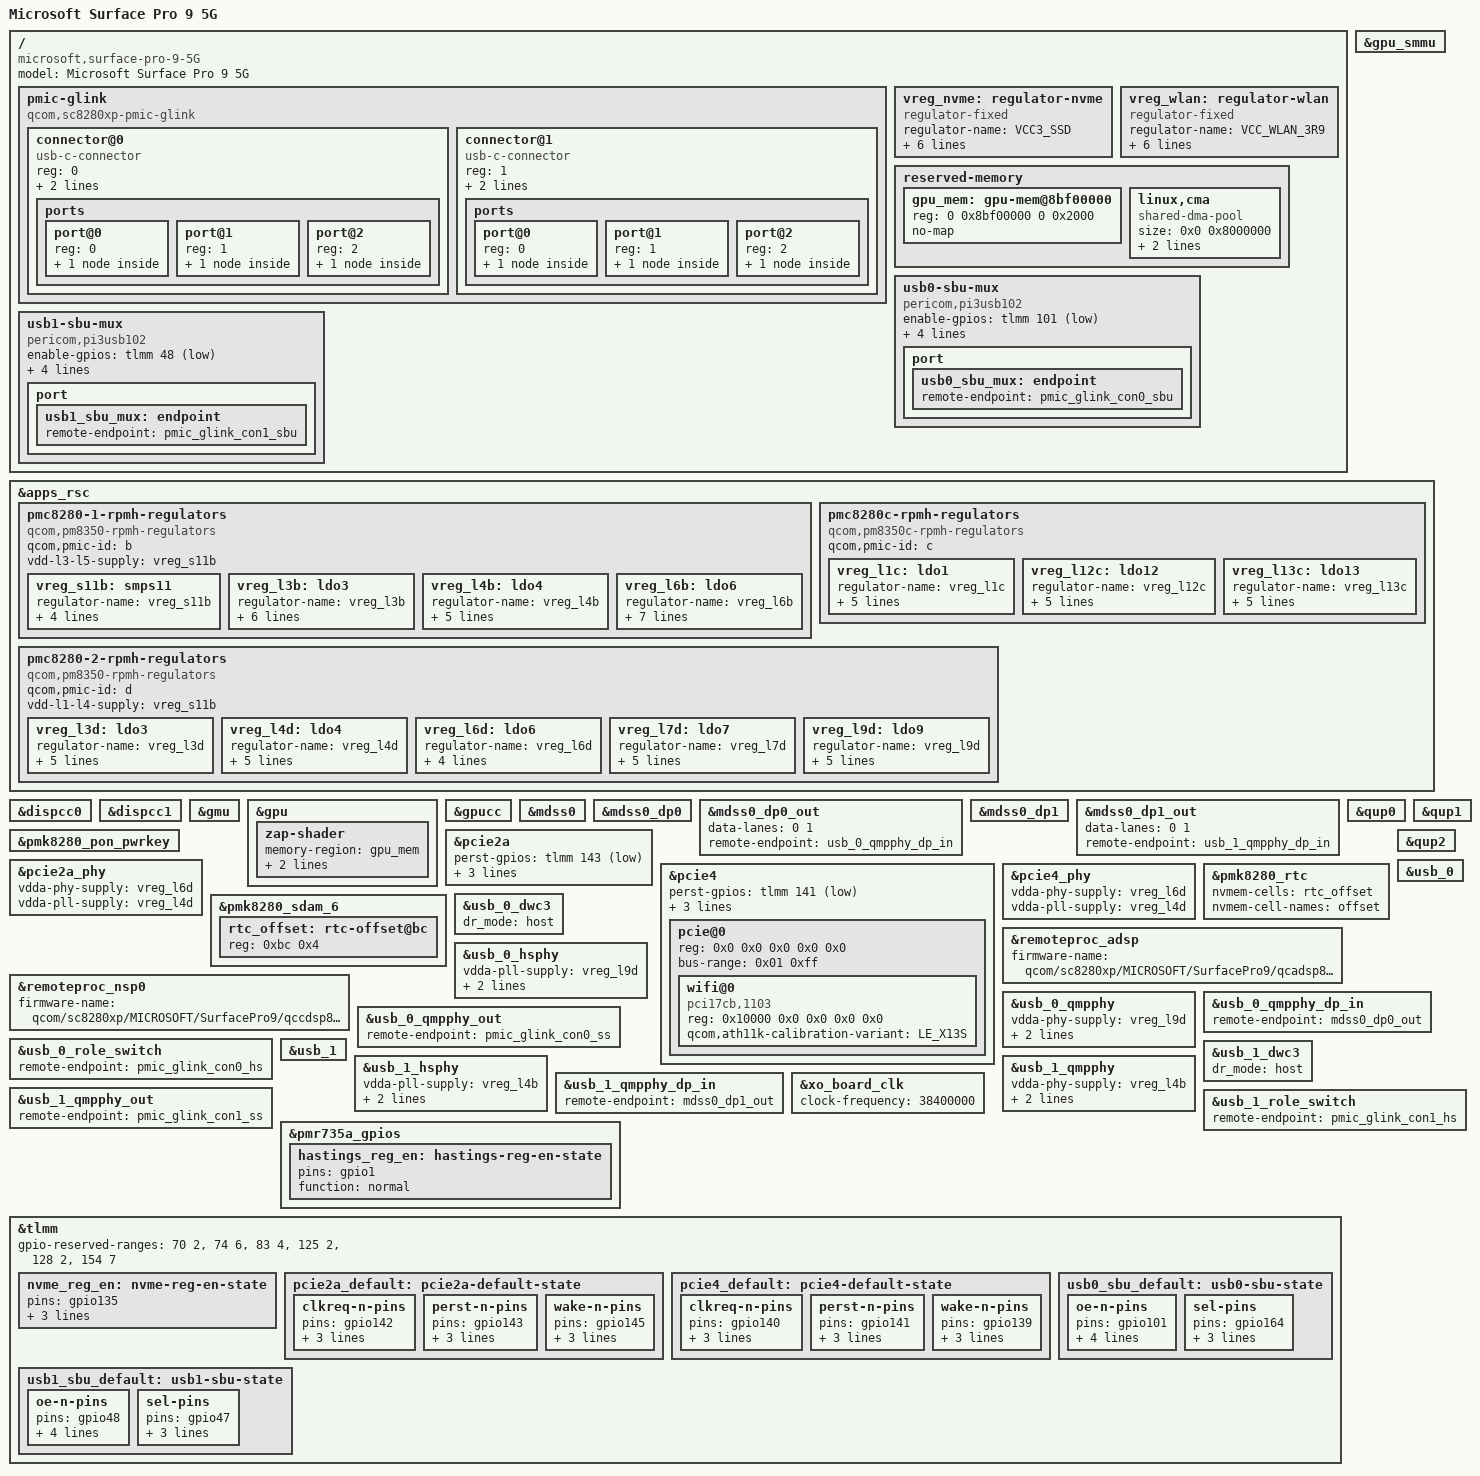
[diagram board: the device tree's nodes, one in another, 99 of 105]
// SPDX-License-Identifier: BSD-3-Clause
/*
 * Copyright (c) 2024, Jérôme de Bretagne <jerome.debretagne@gmail.com>
 */

/dts-v1/;

#include <dt-bindings/gpio/gpio.h>
#include <dt-bindings/regulator/qcom,rpmh-regulator.h>

#include "sc8280xp.dtsi"
#include "sc8280xp-pmics.dtsi"

/ {
	model = "Microsoft Surface Pro 9 5G";
	compatible = "microsoft,surface-pro-9-5G", "qcom,sc8280xp";

	pmic-glink {
		compatible = "qcom,sc8280xp-pmic-glink", "qcom,pmic-glink";

		#address-cells = <1>;
		#size-cells = <0>;

		connector@0 {
			compatible = "usb-c-connector";
			reg = <0>;
			power-role = "dual";
			data-role = "dual";

			ports {
				#address-cells = <1>;
				#size-cells = <0>;

				port@0 {
					reg = <0>;

					pmic_glink_con0_hs: endpoint {
						remote-endpoint = <&usb_0_role_switch>;
					};
				};

				port@1 {
					reg = <1>;

					pmic_glink_con0_ss: endpoint {
						remote-endpoint = <&usb_0_qmpphy_out>;
					};
				};

				port@2 {
					reg = <2>;

					pmic_glink_con0_sbu: endpoint {
						remote-endpoint = <&usb0_sbu_mux>;
					};
				};
			};
		};

		connector@1 {
			compatible = "usb-c-connector";
			reg = <1>;
			power-role = "dual";
			data-role = "dual";

			ports {
				#address-cells = <1>;
				#size-cells = <0>;
				port@0 {
					reg = <0>;

					pmic_glink_con1_hs: endpoint {
						remote-endpoint = <&usb_1_role_switch>;
					};
				};

				port@1 {
					reg = <1>;

					pmic_glink_con1_ss: endpoint {
						remote-endpoint = <&usb_1_qmpphy_out>;
					};
				};

				port@2 {
					reg = <2>;

					pmic_glink_con1_sbu: endpoint {
						remote-endpoint = <&usb1_sbu_mux>;
					};
				};
			};
		};
	};

	vreg_nvme: regulator-nvme {
		compatible = "regulator-fixed";

		regulator-name = "VCC3_SSD";
		regulator-min-microvolt = <3300000>;
		regulator-max-microvolt = <3300000>;

		gpio = <&tlmm 135 GPIO_ACTIVE_HIGH>;
		enable-active-high;

		pinctrl-names = "default";
		pinctrl-0 = <&nvme_reg_en>;

		regulator-boot-on;
	};

	vreg_wlan: regulator-wlan {
		compatible = "regulator-fixed";

		regulator-name = "VCC_WLAN_3R9";
		regulator-min-microvolt = <3900000>;
		regulator-max-microvolt = <3900000>;

		gpio = <&pmr735a_gpios 1 GPIO_ACTIVE_HIGH>;
		enable-active-high;

		pinctrl-names = "default";
		pinctrl-0 = <&hastings_reg_en>;

		regulator-boot-on;
	};

	reserved-memory {
		gpu_mem: gpu-mem@8bf00000 {
			reg = <0 0x8bf00000 0 0x2000>;
			no-map;
		};

		linux,cma {
			compatible = "shared-dma-pool";
			size = <0x0 0x8000000>;
			reusable;
			linux,cma-default;
		};
	};

	usb0-sbu-mux {
		compatible = "pericom,pi3usb102", "gpio-sbu-mux";

		enable-gpios = <&tlmm 101 GPIO_ACTIVE_LOW>;
		select-gpios = <&tlmm 164 GPIO_ACTIVE_HIGH>;

		pinctrl-names = "default";
		pinctrl-0 = <&usb0_sbu_default>;

		mode-switch;
		orientation-switch;

		port {
			usb0_sbu_mux: endpoint {
				remote-endpoint = <&pmic_glink_con0_sbu>;
			};
		};
	};

	usb1-sbu-mux {
		compatible = "pericom,pi3usb102", "gpio-sbu-mux";

		enable-gpios = <&tlmm 48 GPIO_ACTIVE_LOW>;
		select-gpios = <&tlmm 47 GPIO_ACTIVE_HIGH>;

		pinctrl-names = "default";
		pinctrl-0 = <&usb1_sbu_default>;

		mode-switch;
		orientation-switch;

		port {
			usb1_sbu_mux: endpoint {
				remote-endpoint = <&pmic_glink_con1_sbu>;
			};
		};
	};
};

&gpu_smmu {
	status = "okay";
};

&apps_rsc {
	pmc8280-1-rpmh-regulators {
		compatible = "qcom,pm8350-rpmh-regulators";
		qcom,pmic-id = "b";

		vdd-l3-l5-supply = <&vreg_s11b>;

		vreg_s11b: smps11 {
			regulator-name = "vreg_s11b";
			regulator-min-microvolt = <1272000>;
			regulator-max-microvolt = <1272000>;
			regulator-initial-mode = <RPMH_REGULATOR_MODE_HPM>;
		};

		vreg_l3b: ldo3 {
			regulator-name = "vreg_l3b";
			regulator-min-microvolt = <1200000>;
			regulator-max-microvolt = <1200000>;
			regulator-initial-mode = <RPMH_REGULATOR_MODE_HPM>;
			regulator-allow-set-load;
			regulator-boot-on;
		};

		vreg_l4b: ldo4 {
			regulator-name = "vreg_l4b";
			regulator-min-microvolt = <912000>;
			regulator-max-microvolt = <912000>;
			regulator-initial-mode = <RPMH_REGULATOR_MODE_HPM>;
			regulator-allow-set-load;
		};

		vreg_l6b: ldo6 {
			regulator-name = "vreg_l6b";
			regulator-min-microvolt = <880000>;
			regulator-max-microvolt = <880000>;
			regulator-initial-mode = <RPMH_REGULATOR_MODE_HPM>;
			regulator-allow-set-load;
			regulator-boot-on;
			regulator-always-on;	// FIXME: VDD_A_EDP_0_0P9
		};
	};

	pmc8280c-rpmh-regulators {
		compatible = "qcom,pm8350c-rpmh-regulators";
		qcom,pmic-id = "c";

		vreg_l1c: ldo1 {
			regulator-name = "vreg_l1c";
			regulator-min-microvolt = <1800000>;
			regulator-max-microvolt = <1800000>;
			regulator-initial-mode = <RPMH_REGULATOR_MODE_HPM>;
			regulator-allow-set-load;
		};

		vreg_l12c: ldo12 {
			regulator-name = "vreg_l12c";
			regulator-min-microvolt = <1800000>;
			regulator-max-microvolt = <1800000>;
			regulator-initial-mode = <RPMH_REGULATOR_MODE_HPM>;
			regulator-allow-set-load;
		};

		vreg_l13c: ldo13 {
			regulator-name = "vreg_l13c";
			regulator-min-microvolt = <3072000>;
			regulator-max-microvolt = <3072000>;
			regulator-initial-mode = <RPMH_REGULATOR_MODE_HPM>;
			regulator-allow-set-load;
		};
	};

	pmc8280-2-rpmh-regulators {
		compatible = "qcom,pm8350-rpmh-regulators";
		qcom,pmic-id = "d";

		vdd-l1-l4-supply = <&vreg_s11b>;

		vreg_l3d: ldo3 {
			regulator-name = "vreg_l3d";
			regulator-min-microvolt = <1200000>;
			regulator-max-microvolt = <1200000>;
			regulator-initial-mode = <RPMH_REGULATOR_MODE_HPM>;
			regulator-allow-set-load;
		};

		vreg_l4d: ldo4 {
			regulator-name = "vreg_l4d";
			regulator-min-microvolt = <1200000>;
			regulator-max-microvolt = <1200000>;
			regulator-initial-mode = <RPMH_REGULATOR_MODE_HPM>;
			regulator-allow-set-load;
		};

		vreg_l6d: ldo6 {
			regulator-name = "vreg_l6d";
			regulator-min-microvolt = <880000>;
			regulator-max-microvolt = <880000>;
			regulator-initial-mode = <RPMH_REGULATOR_MODE_HPM>;
		};

		vreg_l7d: ldo7 {
			regulator-name = "vreg_l7d";
			regulator-min-microvolt = <3072000>;
			regulator-max-microvolt = <3072000>;
			regulator-initial-mode = <RPMH_REGULATOR_MODE_HPM>;
			regulator-allow-set-load;
		};

		vreg_l9d: ldo9 {
			regulator-name = "vreg_l9d";
			regulator-min-microvolt = <912000>;
			regulator-max-microvolt = <912000>;
			regulator-initial-mode = <RPMH_REGULATOR_MODE_HPM>;
			regulator-allow-set-load;
		};
	};
};

&dispcc0 {
	status = "okay";
};

&dispcc1 {
	status = "okay";
};

&gmu {
	status = "okay";
};

&gpu {
	status = "okay";

	zap-shader {
		memory-region = <&gpu_mem>;
		firmware-name = "qcom/sc8280xp/MICROSOFT/SurfacePro9/qcdxkmsuc8280.mbn";
	};
};

&gpucc {
	status = "okay";
};

&mdss0 {
	status = "okay";
};

&mdss0_dp0 {
	status = "okay";
};

&mdss0_dp0_out {
	data-lanes = <0 1>;
	remote-endpoint = <&usb_0_qmpphy_dp_in>;
};

&mdss0_dp1 {
	status = "okay";
};

&mdss0_dp1_out {
	data-lanes = <0 1>;
	remote-endpoint = <&usb_1_qmpphy_dp_in>;
};

&pmk8280_pon_pwrkey {
	status = "okay";
};

&qup0 {
	status = "okay";
};

&pcie2a {
	perst-gpios = <&tlmm 143 GPIO_ACTIVE_LOW>;
	wake-gpios = <&tlmm 145 GPIO_ACTIVE_LOW>;

	vddpe-3v3-supply = <&vreg_nvme>;

	pinctrl-names = "default";
	pinctrl-0 = <&pcie2a_default>;

	status = "okay";
};

&pcie2a_phy {
	vdda-phy-supply = <&vreg_l6d>;
	vdda-pll-supply = <&vreg_l4d>;

	status = "okay";
};

&pcie4 {
	perst-gpios = <&tlmm 141 GPIO_ACTIVE_LOW>;
	wake-gpios = <&tlmm 139 GPIO_ACTIVE_LOW>;

	vddpe-3v3-supply = <&vreg_wlan>;

	pinctrl-names = "default";
	pinctrl-0 = <&pcie4_default>;

	status = "okay";

	pcie@0 {
		device_type = "pci";
		reg = <0x0 0x0 0x0 0x0 0x0>;
		#address-cells = <3>;
		#size-cells = <2>;
		ranges;

		bus-range = <0x01 0xff>;

		wifi@0 {
			compatible = "pci17cb,1103";
			reg = <0x10000 0x0 0x0 0x0 0x0>;

			qcom,ath11k-calibration-variant = "LE_X13S";
		};
	};
};

&pcie4_phy {
	vdda-phy-supply = <&vreg_l6d>;
	vdda-pll-supply = <&vreg_l4d>;

	status = "okay";
};

&pmk8280_rtc {
	nvmem-cells = <&rtc_offset>;
	nvmem-cell-names = "offset";

	status = "okay";
};

&pmk8280_sdam_6 {
	status = "okay";

	rtc_offset: rtc-offset@bc {
		reg = <0xbc 0x4>;
	};
};

&qup1 {
	status = "okay";
};

&qup2 {
	status = "okay";
};

&remoteproc_adsp {
	firmware-name = "qcom/sc8280xp/MICROSOFT/SurfacePro9/qcadsp8280.mbn";

	status = "okay";
};

&remoteproc_nsp0 {
	firmware-name = "qcom/sc8280xp/MICROSOFT/SurfacePro9/qccdsp8280.mbn";

	status = "okay";
};

&usb_0 {
	status = "okay";
};

&usb_0_dwc3 {
	dr_mode = "host";
};

&usb_0_hsphy {
	vdda-pll-supply = <&vreg_l9d>;
	vdda18-supply = <&vreg_l1c>;
	vdda33-supply = <&vreg_l7d>;

	status = "okay";
};

&usb_0_qmpphy {
	vdda-phy-supply = <&vreg_l9d>;
	vdda-pll-supply = <&vreg_l4d>;

	orientation-switch;

	status = "okay";
};

&usb_0_qmpphy_dp_in {
	remote-endpoint = <&mdss0_dp0_out>;
};

&usb_0_qmpphy_out {
	remote-endpoint = <&pmic_glink_con0_ss>;
};

&usb_0_role_switch {
	remote-endpoint = <&pmic_glink_con0_hs>;
};

&usb_1 {
	status = "okay";
};

&usb_1_dwc3 {
	dr_mode = "host";
};

&usb_1_hsphy {
	vdda-pll-supply = <&vreg_l4b>;
	vdda18-supply = <&vreg_l1c>;
	vdda33-supply = <&vreg_l13c>;

	status = "okay";
};

&usb_1_qmpphy {
	vdda-phy-supply = <&vreg_l4b>;
	vdda-pll-supply = <&vreg_l3b>;

	orientation-switch;

	status = "okay";
};

&usb_1_qmpphy_dp_in {
	remote-endpoint = <&mdss0_dp1_out>;
};

&usb_1_qmpphy_out {
	remote-endpoint = <&pmic_glink_con1_ss>;
};

&usb_1_role_switch {
	remote-endpoint = <&pmic_glink_con1_hs>;
};

&xo_board_clk {
	clock-frequency = <38400000>;
};

/* PINCTRL */

&pmr735a_gpios {
	hastings_reg_en: hastings-reg-en-state {
		pins = "gpio1";
		function = "normal";
	};
};

&tlmm {
	gpio-reserved-ranges = <70 2>, <74 6>, <83 4>, <125 2>, <128 2>, <154 7>;

	nvme_reg_en: nvme-reg-en-state {
		pins = "gpio135";
		function = "gpio";
		drive-strength = <2>;
		bias-disable;
	};

	pcie2a_default: pcie2a-default-state {
		clkreq-n-pins {
			pins = "gpio142";
			function = "pcie2a_clkreq";
			drive-strength = <2>;
			bias-pull-up;
		};

		perst-n-pins {
			pins = "gpio143";
			function = "gpio";
			drive-strength = <2>;
			bias-pull-down;
		};

		wake-n-pins {
		       pins = "gpio145";
		       function = "gpio";
		       drive-strength = <2>;
		       bias-pull-up;
	       };
	};

	pcie4_default: pcie4-default-state {
		clkreq-n-pins {
			pins = "gpio140";
			function = "pcie4_clkreq";
			drive-strength = <2>;
			bias-pull-up;
		};

		perst-n-pins {
			pins = "gpio141";
			function = "gpio";
			drive-strength = <2>;
			bias-pull-down;
		};

		wake-n-pins {
			pins = "gpio139";
			function = "gpio";
			drive-strength = <2>;
			bias-pull-up;
		};
	};

	usb0_sbu_default: usb0-sbu-state {
		oe-n-pins {
			pins = "gpio101";
			function = "gpio";
			bias-disable;
			drive-strength = <16>;
			output-high;
		};

		sel-pins {
			pins = "gpio164";
			function = "gpio";
			bias-disable;
			drive-strength = <16>;
		};
	};

	usb1_sbu_default: usb1-sbu-state {
		oe-n-pins {
			pins = "gpio48";
			function = "gpio";
			bias-disable;
			drive-strength = <16>;
			output-high;
		};

		sel-pins {
			pins = "gpio47";
			function = "gpio";
			bias-disable;
			drive-strength = <16>;
		};
	};
};
